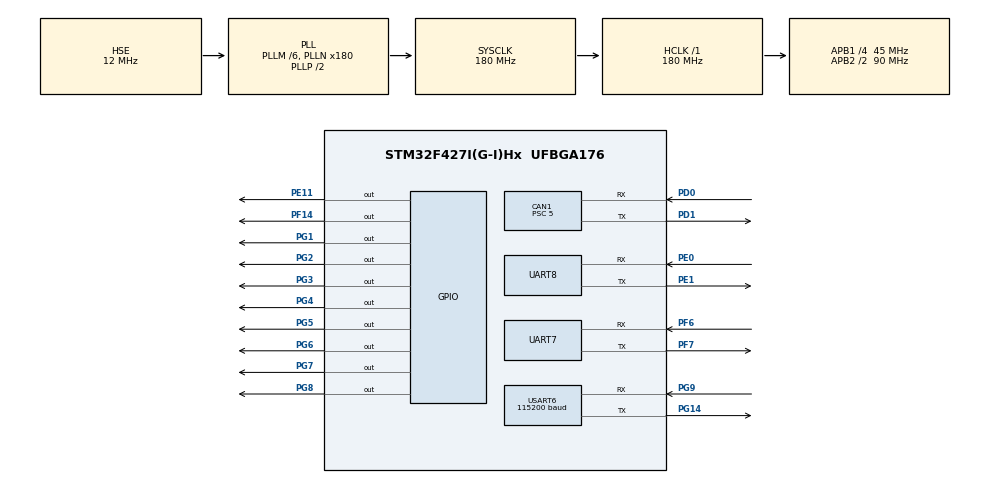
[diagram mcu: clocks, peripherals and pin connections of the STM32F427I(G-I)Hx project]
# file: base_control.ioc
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CAN1.ABOM=ENABLE
CAN1.BS1=CAN_BS1_6TQ
CAN1.BS2=CAN_BS2_2TQ
CAN1.CalculateBaudRate=1000000
CAN1.CalculateTimeBit=1000
CAN1.CalculateTimeQuantum=111.11111111111111
CAN1.Mode=CAN_MODE_NORMAL
CAN1.Prescaler=5
Dma.Request0=USART6_RX
Dma.Request1=UART8_TX
Dma.UART8_TX.1.Direction=DMA_MEMORY_TO_PERIPH
Dma.UART8_TX.1.FIFOMode=DMA_FIFOMODE_DISABLE
Dma.UART8_TX.1.Instance=DMA1_Stream0
Dma.UART8_TX.1.MemDataAlignment=DMA_MDATAALIGN_BYTE
Dma.UART8_TX.1.MemInc=DMA_MINC_ENABLE
Dma.UART8_TX.1.Mode=DMA_CIRCULAR
Dma.UART8_TX.1.PeriphDataAlignment=DMA_PDATAALIGN_BYTE
Dma.UART8_TX.1.PeriphInc=DMA_PINC_DISABLE
Dma.UART8_TX.1.Priority=DMA_PRIORITY_LOW
Dma.USART6_RX.0.Direction=DMA_PERIPH_TO_MEMORY
Dma.USART6_RX.0.FIFOMode=DMA_FIFOMODE_DISABLE
Dma.USART6_RX.0.Instance=DMA2_Stream1
Dma.USART6_RX.0.MemDataAlignment=DMA_MDATAALIGN_BYTE
Dma.USART6_RX.0.MemInc=DMA_MINC_ENABLE
Dma.USART6_RX.0.Mode=DMA_NORMAL
Dma.USART6_RX.0.PeriphDataAlignment=DMA_PDATAALIGN_BYTE
Dma.USART6_RX.0.PeriphInc=DMA_PINC_DISABLE
Dma.USART6_RX.0.Priority=DMA_PRIORITY_LOW
Mcu.Family=STM32F4
Mcu.Name=STM32F427I(G-I)Hx
Mcu.Package=UFBGA176
NVIC.CAN1_RX0_IRQn=true\:11\:0\:true\:false\:true\:true\:true\:true
NVIC.CAN1_RX1_IRQn=true\:12\:0\:true\:false\:true\:true\:true\:true
NVIC.CAN1_SCE_IRQn=true\:10\:0\:true\:false\:true\:true\:true\:true
NVIC.CAN1_TX_IRQn=true\:12\:0\:true\:false\:true\:true\:true\:true
NVIC.DMA1_Stream0_IRQn=true\:5\:0\:true\:false\:true\:false\:true\:true
NVIC.DMA2_Stream1_IRQn=true\:5\:0\:true\:false\:true\:false\:true\:true
NVIC.PriorityGroup=NVIC_PRIORITYGROUP_4
NVIC.TIM8_TRG_COM_TIM14_IRQn=true\:15\:0\:false\:false\:true\:false\:true\:true
NVIC.TimeBase=TIM8_TRG_COM_TIM14_IRQn
NVIC.TimeBaseIP=TIM14
NVIC.UART7_IRQn=true\:0\:0\:false\:false\:true\:true\:true\:true
NVIC.UART8_IRQn=true\:14\:0\:true\:false\:true\:true\:true\:true
NVIC.USART6_IRQn=true\:13\:0\:true\:false\:true\:true\:true\:true
PA13.Mode=Serial_Wire
PA13.Signal=SYS_JTMS-SWDIO
PA14.Mode=Serial_Wire
PA14.Signal=SYS_JTCK-SWCLK
PD0.Mode=CAN_Activate
PD0.Signal=CAN1_RX
PD1.Mode=CAN_Activate
PD1.Signal=CAN1_TX
PE0.Mode=Asynchronous
PE0.Signal=UART8_RX
PE1.Mode=Asynchronous
PE1.Signal=UART8_TX
PE11.PinState=GPIO_PIN_SET
PE11.Signal=GPIO_Output
PF14.PinState=GPIO_PIN_SET
PF14.Signal=GPIO_Output
PF6.Mode=Asynchronous
PF6.Signal=UART7_RX
PF7.Mode=Asynchronous
PF7.Signal=UART7_TX
PG1.PinState=GPIO_PIN_SET
PG1.Signal=GPIO_Output
PG14.Mode=Asynchronous
PG14.Signal=USART6_TX
PG2.PinState=GPIO_PIN_SET
PG2.Signal=GPIO_Output
PG3.PinState=GPIO_PIN_SET
PG3.Signal=GPIO_Output
PG4.PinState=GPIO_PIN_SET
PG4.Signal=GPIO_Output
PG5.PinState=GPIO_PIN_SET
PG5.Signal=GPIO_Output
PG6.PinState=GPIO_PIN_SET
PG6.Signal=GPIO_Output
PG7.PinState=GPIO_PIN_SET
PG7.Signal=GPIO_Output
PG8.PinState=GPIO_PIN_SET
PG8.Signal=GPIO_Output
PG9.Mode=Asynchronous
PG9.Signal=USART6_RX
PH0/OSC_IN.Mode=HSE-External-Oscillator
PH0/OSC_IN.Signal=RCC_OSC_IN
PH1/OSC_OUT.Mode=HSE-External-Oscillator
PH1/OSC_OUT.Signal=RCC_OSC_OUT
ProjectManager.HeapSize=0x200
ProjectManager.StackSize=0x400
ProjectManager.TargetToolchain=CMake
RCC.48MHZClocksFreq_Value=90000000
RCC.AHBFreq_Value=180000000
RCC.APB1CLKDivider=RCC_HCLK_DIV4
RCC.APB1Freq_Value=45000000
RCC.APB1TimFreq_Value=90000000
RCC.APB2CLKDivider=RCC_HCLK_DIV2
RCC.APB2Freq_Value=90000000
RCC.APB2TimFreq_Value=180000000
RCC.CortexFreq_Value=180000000
RCC.HCLKFreq_Value=180000000
RCC.HSE_VALUE=12000000
RCC.HSI_VALUE=16000000
RCC.LSE_VALUE=32768
RCC.PLLM=6
RCC.PLLN=180
RCC.PLLSourceVirtual=RCC_PLLSOURCE_HSE
RCC.SYSCLKFreq_VALUE=180000000
RCC.SYSCLKSource=RCC_SYSCLKSOURCE_PLLCLK
RCC.VCOOutputFreq_Value=360000000
UART7.VirtualMode=Asynchronous
UART8.VirtualMode=Asynchronous
USART6.BaudRate=115200
USART6.VirtualMode=VM_ASYNC
VP_CRC_VS_CRC.Mode=CRC_Activate
VP_SYS_VS_tim14.Mode=TIM14
board=custom

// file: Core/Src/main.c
/* USER CODE BEGIN Header */
/**
  ******************************************************************************
  * @file           : main.c
  * @brief          : Main program body
  ******************************************************************************
  * @attention
  *
  * Copyright (c) 2026 STMicroelectronics.
  * All rights reserved.
  *
  * This software is licensed under terms that can be found in the LICENSE file
  * in the root directory of this software component.
  * If no LICENSE file comes with this software, it is provided AS-IS.
  *
  ******************************************************************************
  */
/* USER CODE END Header */
#include "main.h"
#include "can.h"
#include "crc.h"
#include "dma.h"
#include "usart.h"
#include "gpio.h"

/* USER CODE BEGIN Includes */
#include "FreeRTOS.h"
#include "task.h"
#include "system.h"

/* USER CODE END Includes */

void SystemClock_Config(void);

int main(void)
{

  /* MCU Configuration--------------------------------------------------------*/

  /* Reset of all peripherals, Initializes the Flash interface and the Systick. */
  HAL_Init();

  /* Configure the system clock */
  SystemClock_Config();

  /* Initialize all configured peripherals */
  MX_GPIO_Init();
  MX_DMA_Init();
  MX_USART6_UART_Init();
  MX_UART8_Init();
  MX_CAN1_Init();
  MX_UART7_Init();
  MX_CRC_Init();
  /* USER CODE BEGIN 2 */

  systemLaunch();

  vTaskStartScheduler();

  /* 永远不要到达这里 */
  HAL_GPIO_WritePin(GPIOF, GPIO_PIN_14, GPIO_PIN_RESET);
  HAL_GPIO_WritePin(GPIOE, GPIO_PIN_11, GPIO_PIN_RESET);
  /* USER CODE END 2 */

  /* Infinite loop */
  while (1)
  {

  }
}

void SystemClock_Config(void)
{
  RCC_OscInitTypeDef RCC_OscInitStruct = {0};
  RCC_ClkInitTypeDef RCC_ClkInitStruct = {0};

  /** Configure the main internal regulator output voltage
  */
  __HAL_RCC_PWR_CLK_ENABLE();
  __HAL_PWR_VOLTAGESCALING_CONFIG(PWR_REGULATOR_VOLTAGE_SCALE1);

  /** Initializes the RCC Oscillators according to the specified parameters
  * in the RCC_OscInitTypeDef structure.
  */
  RCC_OscInitStruct.OscillatorType = RCC_OSCILLATORTYPE_HSE;
  RCC_OscInitStruct.HSEState = RCC_HSE_ON;
  RCC_OscInitStruct.PLL.PLLState = RCC_PLL_ON;
  RCC_OscInitStruct.PLL.PLLSource = RCC_PLLSOURCE_HSE;
  RCC_OscInitStruct.PLL.PLLM = 6;
  RCC_OscInitStruct.PLL.PLLN = 180;
  RCC_OscInitStruct.PLL.PLLP = RCC_PLLP_DIV2;
  RCC_OscInitStruct.PLL.PLLQ = 4;
  if (HAL_RCC_OscConfig(&RCC_OscInitStruct) != HAL_OK)
  {
    Error_Handler();
  }

  /** Activate the Over-Drive mode
  */
  if (HAL_PWREx_EnableOverDrive() != HAL_OK)
  {
    Error_Handler();
  }

  /** Initializes the CPU, AHB and APB buses clocks
  */
  RCC_ClkInitStruct.ClockType = RCC_CLOCKTYPE_HCLK|RCC_CLOCKTYPE_SYSCLK
                              |RCC_CLOCKTYPE_PCLK1|RCC_CLOCKTYPE_PCLK2;
  RCC_ClkInitStruct.SYSCLKSource = RCC_SYSCLKSOURCE_PLLCLK;
  RCC_ClkInitStruct.AHBCLKDivider = RCC_SYSCLK_DIV1;
  RCC_ClkInitStruct.APB1CLKDivider = RCC_HCLK_DIV4;
  RCC_ClkInitStruct.APB2CLKDivider = RCC_HCLK_DIV2;

  if (HAL_RCC_ClockConfig(&RCC_ClkInitStruct, FLASH_LATENCY_5) != HAL_OK)
  {
    Error_Handler();
  }
}

void HAL_TIM_PeriodElapsedCallback(TIM_HandleTypeDef *htim)
{
  if (htim->Instance == TIM14)
  {
    HAL_IncTick();
  }
}

void Error_Handler(void)
{
  __disable_irq();
  while (1)
  {
  }
}
